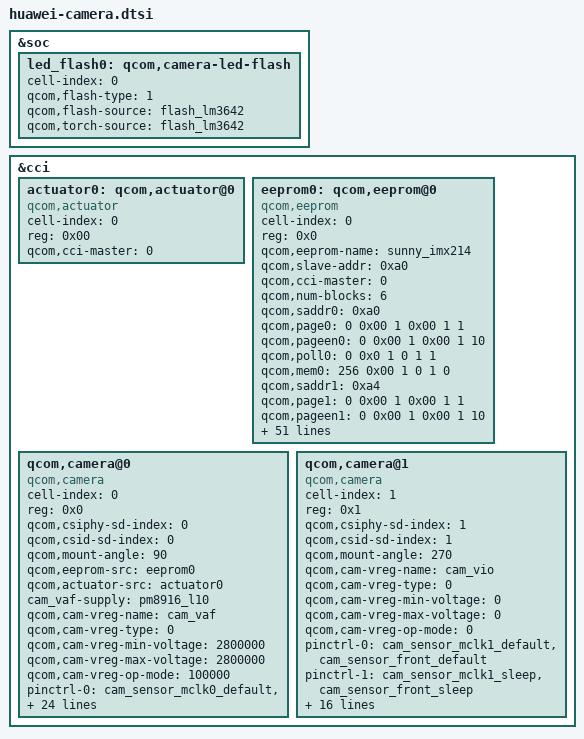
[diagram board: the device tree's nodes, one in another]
/*
 * Copyright (c) 2014, The Linux Foundation. All rights reserved.
 *
 * This program is free software; you can redistribute it and/or modify
 * it under the terms of the GNU General Public License version 2 and
 * only version 2 as published by the Free Software Foundation.
 *
 * This program is distributed in the hope that it will be useful,
 * but WITHOUT ANY WARRANTY; without even the implied warranty of
 * MERCHANTABILITY or FITNESS FOR A PARTICULAR PURPOSE.  See the
 * GNU General Public License for more details.
 */

&soc {
        led_flash0: qcom,camera-led-flash {
                cell-index = <0>;
                /*compatible = "qcom,camera-led-flash";*/
                qcom,flash-type = <1>;
                qcom,flash-source = <&flash_lm3642>;
                qcom,torch-source = <&flash_lm3642>;
        };
	/*move some lines */
};

&cci {
	actuator0: qcom,actuator@0 {
		cell-index = <0>;
		reg = <0x00>;
		compatible = "qcom,actuator";
		qcom,cci-master = <0>;
	};
	eeprom0: qcom,eeprom@0 {
			cell-index = <0>;
			reg = <0x0>; //a fake addr for register, mclk src already defined 6-0060.
			qcom,eeprom-name = "sunny_imx214";
			compatible = "qcom,eeprom";
			qcom,slave-addr = <0xa0>;
			qcom,cci-master = <0>;
			qcom,num-blocks = <6>;
			qcom,saddr0 = <0xa0>;
			qcom,page0 = <0 0x00 1 0x00 1 1>;
			qcom,pageen0 = <0 0x00 1 0x00 1 10>;
			qcom,poll0 = <0 0x0 1 0 1 1>;
			qcom,mem0 = <256 0x00 1 0 1 0>;

			qcom,saddr1 = <0xa4>;
			qcom,page1 = <0 0x00 1 0x00 1 1>;
			qcom,pageen1 = <0 0x00 1 0x00 1 10>;
			qcom,poll1 = <0 0x0 1 0 1 1>;
			qcom,mem1 = <256 0x00 1 0 1 0>;

			qcom,saddr2 = <0xa6>;
			qcom,page2 = <0 0x00 1 0x00 1 1>;
			qcom,pageen2 = <0 0x00 1 0x00 1 10>;
			qcom,poll2 = <0 0x0 1 0 1 1>;
			qcom,mem2 = <256 0x00 1 0 1 0>;

			qcom,saddr3 = <0xa8>;
			qcom,page3 = <0 0x00 1 0x00 1 1>;
			qcom,pageen3 = <0 0x00 1 0x00 1 10>;
			qcom,poll3 = <0 0x0 1 0 1 1>;
			qcom,mem3 = <256 0x00 1 0 1 0>;

			qcom,saddr4 = <0xaa>;
			qcom,page4 = <0 0x00 1 0x00 1 1>;
			qcom,pageen4 = <0 0x00 1 0x00 1 10>;
			qcom,poll4 = <0 0x0 1 0 1 1>;
			qcom,mem4 = <256 0x00 1 0 1 0>;

			qcom,saddr5 = <0xac>;
			qcom,page5 = <0 0x00 1 0x00 1 1>;
			qcom,pageen5 = <0 0x00 1 0x00 1 10>;
			qcom,poll5 = <0 0x0 1 0 1 1>;
			qcom,mem5 = <5 0x00 1 0 1 0>;

			qcom,cam-vreg-name = "cam_vio", "cam_vana";
			qcom,cam-vreg-type = <1 0>;
			qcom,cam-vreg-min-voltage = <0 2850000>;
			qcom,cam-vreg-max-voltage = <0 2850000>;
			qcom,cam-vreg-op-mode = <0 80000>;
			pinctrl-names = "cam_default", "cam_suspend";
			pinctrl-0 = <&cam_sensor_mclk0_default
					&cam_sensor_rear_default>;
			pinctrl-1 = <&cam_sensor_mclk0_sleep &cam_sensor_rear_sleep>;
			gpios = <&msm_gpio 26 0>,
				<&msm_gpio 35 0>,
				<&msm_gpio 34 0>,
				<&msm_gpio 114 0>,
				<&msm_gpio 110 0>;
			qcom,gpio-reset = <1>;
			qcom,gpio-standby = <2>;
			qcom,gpio-vio = <3>;
			qcom,gpio-vana = <4>;
			qcom,gpio-req-tbl-num = <0 1 2 3 4>;
			qcom,gpio-req-tbl-flags = <1 0 0 0 0 >;
			qcom,gpio-req-tbl-label = "CAMIF_MCLK0",
				"MCAM_RESET",
				"MCAM_STANDBY",
				"CAM_LDO_VIO",
				"CAM_LDO_VANA";
			qcom,cam-power-seq-type = "sensor_gpio","sensor_gpio","sensor_gpio","sensor_clk";
			qcom,cam-power-seq-val = "sensor_gpio_vio", "sensor_gpio_vana",
				"sensor_gpio_reset",
				"sensor_cam_mclk" ;
			qcom,cam-power-seq-cfg-val = <1 1 1 24000000>;
			qcom,cam-power-seq-delay = <1 1 10 5>;
			clocks = <&clock_gcc clk_mclk0_clk_src>,
					<&clock_gcc clk_gcc_camss_mclk0_clk>;
			clock-names = "cam_src_clk", "cam_clk";
		};
	qcom,camera@0 {
		cell-index = <0>;
		compatible = "qcom,camera";
		reg = <0x0>;
		qcom,csiphy-sd-index = <0>;
		qcom,csid-sd-index = <0>;
		qcom,mount-angle = <90>;
		qcom,eeprom-src = <&eeprom0>;
		qcom,actuator-src = <&actuator0>;
		/*move some lines */
		cam_vaf-supply = <&pm8916_l10>;
		qcom,cam-vreg-name = "cam_vaf";
		qcom,cam-vreg-type = <0>;
		qcom,cam-vreg-min-voltage = <2800000>;
		qcom,cam-vreg-max-voltage = <2800000>;
		qcom,cam-vreg-op-mode = <100000>;
		pinctrl-names = "cam_default", "cam_suspend";
		pinctrl-0 = <&cam_sensor_mclk0_default
				&cam_sensor_rear_default>;
		pinctrl-1 = <&cam_sensor_mclk0_sleep &cam_sensor_rear_sleep>;
		gpios = <&msm_gpio 26 0>,
			<&msm_gpio 35 0>,
			<&msm_gpio 34 0>,
			<&msm_gpio 121 0>,
			<&msm_gpio 114 0>,
			<&msm_gpio 110 0>,
			<&msm_gpio 120 0>,
			<&msm_gpio 51 0>;
		qcom,gpio-reset = <1>;
		qcom,gpio-standby = <2>;
		qcom,gpio-vdig = <3>;
		qcom,gpio-vio = <4>;
		qcom,gpio-vana = <5>;
		qcom,gpio-af-pwdm = <6>;
		qcom,gpio-cam-id = <7>;
		qcom,gpio-req-tbl-num = <0 1 2 3 4 5 6 7>;
		qcom,gpio-req-tbl-flags = <1 0 0 0 0 0 0 1>;
		qcom,gpio-req-tbl-label = "CAMIF_MCLK0",
			"MCAM_RESET",
			"MCAM_STANDBY",
			"CAM_LDO_VDIG",
			"CAM_LDO_VIO",
			"CAM_LDO_VANA",
			"MCAM_AF_PWDM",
			"CAM_CAM_ID";
		qcom,sensor-position = <0>;
		qcom,sensor-mode = <0>;
		qcom,cci-master = <0>;
		status = "ok";
		clocks = <&clock_gcc clk_mclk0_clk_src>,
				<&clock_gcc clk_gcc_camss_mclk0_clk>;
		clock-names = "cam_src_clk", "cam_clk";
	};

	qcom,camera@1 {
		cell-index = <1>;
		compatible = "qcom,camera";
		reg = <0x1>;
		qcom,csiphy-sd-index = <1>;
		qcom,csid-sd-index = <1>;
		qcom,mount-angle = <270>;
//		qcom,eeprom-src = <&eeprom1>;
		//qcom,cam-vreg-name not use but can not be empty,so add some stuff
		qcom,cam-vreg-name = "cam_vio";
		qcom,cam-vreg-type = <0>;
		qcom,cam-vreg-min-voltage = <0>;
		qcom,cam-vreg-max-voltage = <0>;
		qcom,cam-vreg-op-mode = <0>;
		pinctrl-names = "cam_default", "cam_suspend";
		pinctrl-0 = <&cam_sensor_mclk1_default &cam_sensor_front_default>;
		pinctrl-1 = <&cam_sensor_mclk1_sleep &cam_sensor_front_sleep>;
		gpios = <&msm_gpio 27 0>,
			<&msm_gpio 28 0>,
			<&msm_gpio 33 0>,
			<&msm_gpio 114 0>,
			<&msm_gpio 110 0>;
			qcom,gpio-reset = <1>;
		qcom,gpio-standby = <2>;
		qcom,gpio-vio = <3>;
		qcom,gpio-vana = <4>;
		qcom,gpio-req-tbl-num = <0 1 2 3 4>;
		qcom,gpio-req-tbl-flags = <1 0 0 0 0>;
		qcom,gpio-req-tbl-label = "CAMIF_MCLK1",
			"SCAM_RESET",
			"SCAM_STANDBY",
			"CAM_LDO_VIO",
			"CAM_LDO_VANA";

		qcom,sensor-position = <1>;
		qcom,sensor-mode = <0>;
		qcom,cci-master = <0>;
		status = "ok";
		clocks = <&clock_gcc clk_mclk1_clk_src>,
				<&clock_gcc clk_gcc_camss_mclk1_clk>;
		clock-names = "cam_src_clk", "cam_clk";
	};

};
